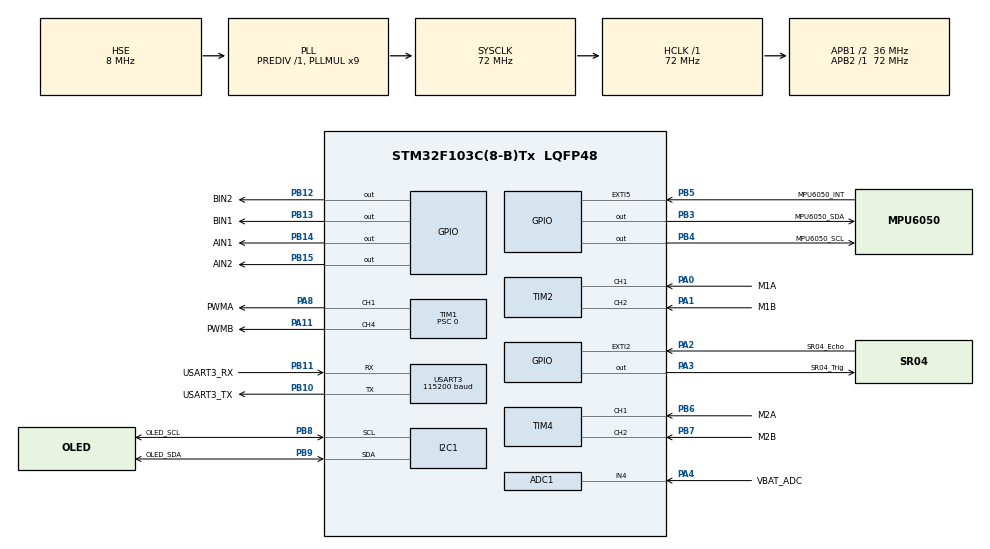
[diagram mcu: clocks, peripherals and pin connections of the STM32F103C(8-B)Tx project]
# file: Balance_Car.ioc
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ADC1.Channel-0\#ChannelRegularConversion=ADC_CHANNEL_4
ADC1.NbrOfConversionFlag=1
ADC1.Rank-0\#ChannelRegularConversion=1
ADC1.SamplingTime-0\#ChannelRegularConversion=ADC_SAMPLETIME_239CYCLES_5
ADC1.master=1
FREERTOS.Tasks01=defaultTask,24,256,StartDefaultTask,Default,NULL,Dynamic,NULL,NULL;BalanceTask,40,256,StartBalanceTask,Default,NULL,Dynamic,NULL,NULL
FREERTOS.configTOTAL_HEAP_SIZE=8192
I2C1.I2C_Mode=I2C_Fast
Mcu.Family=STM32F1
Mcu.Name=STM32F103C(8-B)Tx
Mcu.Package=LQFP48
NVIC.EXTI2_IRQn=true\:7\:0\:true\:false\:true\:false\:true\:true\:true
NVIC.EXTI9_5_IRQn=true\:5\:0\:true\:false\:true\:false\:true\:true\:true
NVIC.PriorityGroup=NVIC_PRIORITYGROUP_4
NVIC.TimeBase=TIM3_IRQn
NVIC.TimeBaseIP=TIM3
NVIC.USART3_IRQn=true\:6\:0\:true\:false\:true\:true\:true\:true\:true
PA0-WKUP.GPIO_Label=M1A
PA0-WKUP.GPIO_PuPd=GPIO_PULLUP
PA0-WKUP.Signal=S_TIM2_CH1_ETR
PA1.GPIO_Label=M1B
PA1.GPIO_PuPd=GPIO_PULLUP
PA1.Signal=S_TIM2_CH2
PA11.GPIO_Label=PWMB
PA11.Signal=S_TIM1_CH4
PA13.Mode=Serial_Wire
PA13.Signal=SYS_JTMS-SWDIO
PA14.Mode=Serial_Wire
PA14.Signal=SYS_JTCK-SWCLK
PA2.GPIO_Label=SR04_Echo
PA2.GPIO_ModeDefaultEXTI=GPIO_MODE_IT_RISING_FALLING
PA2.GPIO_PuPd=GPIO_PULLDOWN
PA2.Signal=GPXTI2
PA3.GPIO_Label=SR04_Trig
PA3.Signal=GPIO_Output
PA4.GPIO_Label=VBAT_ADC
PA4.Signal=ADCx_IN4
PA8.GPIO_Label=PWMA
PA8.Signal=S_TIM1_CH1
PB10.GPIO_Label=USART3_TX
PB10.Mode=Asynchronous
PB10.Signal=USART3_TX
PB11.GPIO_Label=USART3_RX
PB11.Mode=Asynchronous
PB11.Signal=USART3_RX
PB12.GPIO_Label=BIN2
PB12.Signal=GPIO_Output
PB13.GPIO_Label=BIN1
PB13.Signal=GPIO_Output
PB14.GPIO_Label=AIN1
PB14.Signal=GPIO_Output
PB15.GPIO_Label=AIN2
PB15.Signal=GPIO_Output
PB3.GPIO_Label=MPU6050_SDA
PB3.GPIO_ModeDefaultOutputPP=GPIO_MODE_OUTPUT_OD
PB3.GPIO_PuPd=GPIO_PULLUP
PB3.PinState=GPIO_PIN_SET
PB3.Signal=GPIO_Output
PB4.GPIO_Label=MPU6050_SCL
PB4.GPIO_ModeDefaultOutputPP=GPIO_MODE_OUTPUT_OD
PB4.GPIO_PuPd=GPIO_PULLUP
PB4.PinState=GPIO_PIN_SET
PB4.Signal=GPIO_Output
PB5.GPIO_Label=MPU6050_INT
PB5.GPIO_ModeDefaultEXTI=GPIO_MODE_IT_FALLING
PB5.Signal=GPXTI5
PB6.GPIO_Label=M2A
PB6.GPIO_PuPd=GPIO_PULLUP
PB6.Signal=S_TIM4_CH1
PB7.GPIO_Label=M2B
PB7.GPIO_PuPd=GPIO_PULLUP
PB7.Signal=S_TIM4_CH2
PB8.GPIO_Label=OLED_SCL
PB8.Mode=I2C
PB8.Signal=I2C1_SCL
PB9.GPIO_Label=OLED_SDA
PB9.Mode=I2C
PB9.Signal=I2C1_SDA
PD0-OSC_IN.Mode=HSE-External-Oscillator
PD0-OSC_IN.Signal=RCC_OSC_IN
PD1-OSC_OUT.Mode=HSE-External-Oscillator
PD1-OSC_OUT.Signal=RCC_OSC_OUT
ProjectManager.HeapSize=0x800
ProjectManager.StackSize=0x1000
ProjectManager.TargetToolchain=MDK-ARM V5.32
RCC.ADCPresc=RCC_ADCPCLK2_DIV6
RCC.AHBFreq_Value=72000000
RCC.APB1CLKDivider=RCC_HCLK_DIV2
RCC.APB1Freq_Value=36000000
RCC.APB1TimFreq_Value=72000000
RCC.APB2Freq_Value=72000000
RCC.APB2TimFreq_Value=72000000
RCC.HCLKFreq_Value=72000000
RCC.PLLMUL=RCC_PLL_MUL9
RCC.PLLSourceVirtual=RCC_PLLSOURCE_HSE
RCC.SYSCLKFreq_VALUE=72000000
RCC.SYSCLKSource=RCC_SYSCLKSOURCE_PLLCLK
RCC.USBFreq_Value=72000000
SH.ADCx_IN4.0=ADC1_IN4,IN4
SH.S_TIM1_CH1.0=TIM1_CH1,PWM Generation1 CH1
SH.S_TIM1_CH4.0=TIM1_CH4,PWM Generation4 CH4
SH.S_TIM2_CH1_ETR.0=TIM2_CH1,Encoder_Interface
SH.S_TIM2_CH2.0=TIM2_CH2,Encoder_Interface
SH.S_TIM4_CH1.0=TIM4_CH1,Encoder_Interface
SH.S_TIM4_CH2.0=TIM4_CH2,Encoder_Interface
TIM1.AutoReloadPreload=TIM_AUTORELOAD_PRELOAD_ENABLE
TIM1.Channel-PWM\ Generation1\ CH1=TIM_CHANNEL_1
TIM1.Channel-PWM\ Generation4\ CH4=TIM_CHANNEL_4
TIM1.Period=7199
TIM1.Prescaler=0
TIM2.AutoReloadPreload=TIM_AUTORELOAD_PRELOAD_ENABLE
TIM2.EncoderMode=TIM_ENCODERMODE_TI12
TIM2.IC1Filter=4
TIM2.IC2Filter=4
TIM4.AutoReloadPreload=TIM_AUTORELOAD_PRELOAD_ENABLE
TIM4.EncoderMode=TIM_ENCODERMODE_TI12
TIM4.IC1Filter=4
TIM4.IC2Filter=4
USART3.BaudRate=115200
USART3.VirtualMode=VM_ASYNC
VP_FREERTOS_VS_CMSIS_V2.Mode=CMSIS_V2
VP_SYS_VS_tim3.Mode=TIM3
board=custom

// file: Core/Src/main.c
/* USER CODE BEGIN Header */
/**
  ******************************************************************************
  * @file           : main.c
  * @brief          : Main program body
  ******************************************************************************
  * @attention
  *
  * Copyright (c) 2026 STMicroelectronics.
  * All rights reserved.
  *
  * This software is licensed under terms that can be found in the LICENSE file
  * in the root directory of this software component.
  * If no LICENSE file comes with this software, it is provided AS-IS.
  *
  ******************************************************************************
  */
/* USER CODE END Header */
#include "main.h"
#include "cmsis_os.h"
#include "adc.h"
#include "i2c.h"
#include "tim.h"
#include "usart.h"
#include "gpio.h"

/* USER CODE BEGIN Includes */
#include "app_sensor_display.h"
/* USER CODE END Includes */

void SystemClock_Config(void);
void MX_FREERTOS_Init(void);

int main(void)
{

  /* MCU Configuration--------------------------------------------------------*/

  /* Reset of all peripherals, Initializes the Flash interface and the Systick. */
  HAL_Init();

  /* Configure the system clock */
  SystemClock_Config();

  /* Initialize all configured peripherals */
  MX_GPIO_Init();
  MX_ADC1_Init();
  MX_I2C1_Init();
  MX_TIM1_Init();
  MX_USART3_UART_Init();
  MX_TIM2_Init();
  MX_TIM4_Init();
  /* USER CODE BEGIN 2 */
  /* BSP init is done before osKernelStart(): HAL_Delay() is still safe here. */
  App_SensorDisplay_Init();
  /* USER CODE END 2 */

  /* Init scheduler */
  osKernelInitialize();  /* Call init function for freertos objects (in cmsis_os2.c) */
  MX_FREERTOS_Init();

  /* Start scheduler */
  osKernelStart();

  /* We should never get here as control is now taken by the scheduler */

  /* Infinite loop */
  while (1)
  {

  }
}

void SystemClock_Config(void)
{
  RCC_OscInitTypeDef RCC_OscInitStruct = {0};
  RCC_ClkInitTypeDef RCC_ClkInitStruct = {0};
  RCC_PeriphCLKInitTypeDef PeriphClkInit = {0};

  /** Initializes the RCC Oscillators according to the specified parameters
  * in the RCC_OscInitTypeDef structure.
  */
  RCC_OscInitStruct.OscillatorType = RCC_OSCILLATORTYPE_HSE;
  RCC_OscInitStruct.HSEState = RCC_HSE_ON;
  RCC_OscInitStruct.HSEPredivValue = RCC_HSE_PREDIV_DIV1;
  RCC_OscInitStruct.HSIState = RCC_HSI_ON;
  RCC_OscInitStruct.PLL.PLLState = RCC_PLL_ON;
  RCC_OscInitStruct.PLL.PLLSource = RCC_PLLSOURCE_HSE;
  RCC_OscInitStruct.PLL.PLLMUL = RCC_PLL_MUL9;
  if (HAL_RCC_OscConfig(&RCC_OscInitStruct) != HAL_OK)
  {
    Error_Handler();
  }

  /** Initializes the CPU, AHB and APB buses clocks
  */
  RCC_ClkInitStruct.ClockType = RCC_CLOCKTYPE_HCLK|RCC_CLOCKTYPE_SYSCLK
                              |RCC_CLOCKTYPE_PCLK1|RCC_CLOCKTYPE_PCLK2;
  RCC_ClkInitStruct.SYSCLKSource = RCC_SYSCLKSOURCE_PLLCLK;
  RCC_ClkInitStruct.AHBCLKDivider = RCC_SYSCLK_DIV1;
  RCC_ClkInitStruct.APB1CLKDivider = RCC_HCLK_DIV2;
  RCC_ClkInitStruct.APB2CLKDivider = RCC_HCLK_DIV1;

  if (HAL_RCC_ClockConfig(&RCC_ClkInitStruct, FLASH_LATENCY_2) != HAL_OK)
  {
    Error_Handler();
  }
  PeriphClkInit.PeriphClockSelection = RCC_PERIPHCLK_ADC;
  PeriphClkInit.AdcClockSelection = RCC_ADCPCLK2_DIV6;
  if (HAL_RCCEx_PeriphCLKConfig(&PeriphClkInit) != HAL_OK)
  {
    Error_Handler();
  }
}

void HAL_TIM_PeriodElapsedCallback(TIM_HandleTypeDef *htim)
{
  if (htim->Instance == TIM3)
  {
    HAL_IncTick();
  }
}

void Error_Handler(void)
{
  __disable_irq();
  while (1)
  {
  }
}

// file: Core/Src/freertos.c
/* USER CODE BEGIN Header */
/**
  ******************************************************************************
  * File Name          : freertos.c
  * Description        : Code for freertos applications
  ******************************************************************************
  * @attention
  *
  * Copyright (c) 2026 STMicroelectronics.
  * All rights reserved.
  *
  * This software is licensed under terms that can be found in the LICENSE file
  * in the root directory of this software component.
  * If no LICENSE file comes with this software, it is provided AS-IS.
  *
  ******************************************************************************
  */
/* USER CODE END Header */

#include "FreeRTOS.h"
#include "task.h"
#include "main.h"
#include "cmsis_os.h"

/* USER CODE BEGIN Includes */
#include "app_sensor_display.h"
#include "app_balance.h"
/* USER CODE END Includes */

/* Definitions for defaultTask */
osThreadId_t defaultTaskHandle;
const osThreadAttr_t defaultTask_attributes = {
  .name = "defaultTask",
  .stack_size = 256 * 4,
  .priority = (osPriority_t) osPriorityNormal,
};
/* Definitions for BalanceTask */
osThreadId_t BalanceTaskHandle;
const osThreadAttr_t BalanceTask_attributes = {
  .name = "BalanceTask",
  .stack_size = 256 * 4,
  .priority = (osPriority_t) osPriorityHigh,
};

void StartDefaultTask(void *argument);
void StartBalanceTask(void *argument);

void MX_FREERTOS_Init(void); /* (MISRA C 2004 rule 8.1) */

void MX_FREERTOS_Init(void) {

  /* Create the thread(s) */
  /* creation of defaultTask */
  defaultTaskHandle = osThreadNew(StartDefaultTask, NULL, &defaultTask_attributes);

  /* creation of BalanceTask */
  BalanceTaskHandle = osThreadNew(StartBalanceTask, NULL, &BalanceTask_attributes);

}

void StartDefaultTask(void *argument)
{
  /* USER CODE BEGIN StartDefaultTask */
  /* Sensor -> OLED display demo. This function never returns. */
  App_SensorDisplay_Loop();
  /* USER CODE END StartDefaultTask */
}

void StartBalanceTask(void *argument)
{
  /* USER CODE BEGIN StartBalanceTask */
  /* Fixed 200 Hz control loop (5 ms). vTaskDelayUntil keeps the period
   * steady instead of accumulating osDelay drift. This task has higher
   * priority than defaultTask so the loop is not blocked by OLED refresh. */
  TickType_t xLastWake = xTaskGetTickCount();
  const TickType_t xPeriod = pdMS_TO_TICKS(5U);

  for(;;)
  {
    App_Balance_Tick(HAL_GetTick());
    vTaskDelayUntil(&xLastWake, xPeriod);
  }
  /* USER CODE END StartBalanceTask */
}
